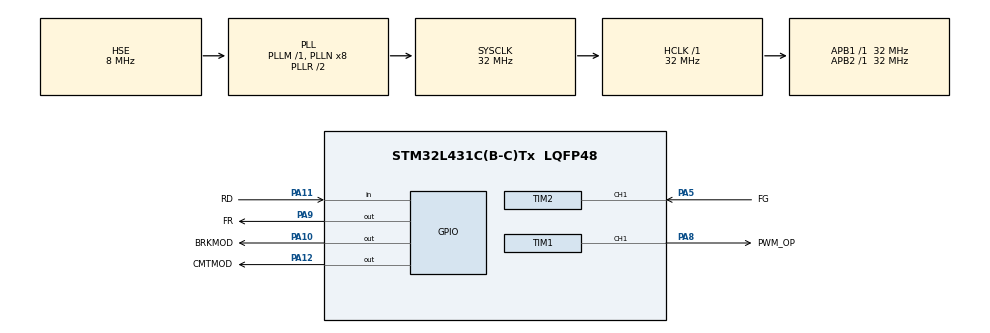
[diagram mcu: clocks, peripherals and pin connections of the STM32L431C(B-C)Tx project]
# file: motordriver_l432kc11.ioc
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Mcu.Family=STM32L4
Mcu.Name=STM32L431C(B-C)Tx
Mcu.Package=LQFP48
NVIC.PriorityGroup=NVIC_PRIORITYGROUP_4
NVIC.TIM2_IRQn=true\:0\:0\:false\:false\:true\:true\:true\:true
PA10.GPIO_Label=BRKMOD
PA10.Signal=GPIO_Output
PA11.GPIO_Label=RD
PA11.Signal=GPIO_Input
PA12.GPIO_Label=CMTMOD
PA12.Signal=GPIO_Output
PA13\ (JTMS-SWDIO).Mode=JTAG_5_pins
PA13\ (JTMS-SWDIO).Signal=SYS_JTMS-SWDIO
PA14\ (JTCK-SWCLK).Mode=JTAG_5_pins
PA14\ (JTCK-SWCLK).Signal=SYS_JTCK-SWCLK
PA15\ (JTDI).Mode=JTAG_5_pins
PA15\ (JTDI).Signal=SYS_JTDI
PA5.GPIO_Label=FG
PA5.Signal=S_TIM2_CH1
PA8.GPIO_Label=PWM_OP
PA8.Signal=S_TIM1_CH1
PA9.GPIO_Label=FR
PA9.Signal=GPIO_Output
PB3\ (JTDO-TRACESWO).Mode=JTAG_5_pins
PB3\ (JTDO-TRACESWO).Signal=SYS_JTDO-SWO
PB4\ (NJTRST).Mode=JTAG_5_pins
PB4\ (NJTRST).Signal=SYS_JTRST
PH0-OSC_IN\ (PH0).Mode=HSE-External-Oscillator
PH0-OSC_IN\ (PH0).Signal=RCC_OSC_IN
PH1-OSC_OUT\ (PH1).Mode=HSE-External-Oscillator
PH1-OSC_OUT\ (PH1).Signal=RCC_OSC_OUT
ProjectManager.HeapSize=0x200
ProjectManager.StackSize=0x400
ProjectManager.TargetToolchain=STM32CubeIDE
RCC.ADCFreq_Value=32000000
RCC.AHBFreq_Value=32000000
RCC.APB1Freq_Value=32000000
RCC.APB1TimFreq_Value=32000000
RCC.APB2Freq_Value=32000000
RCC.APB2TimFreq_Value=32000000
RCC.CortexFreq_Value=32000000
RCC.HCLKFreq_Value=32000000
RCC.HSE_VALUE=8000000
RCC.HSI48_VALUE=48000000
RCC.HSI_VALUE=16000000
RCC.LSE_VALUE=32768
RCC.MSI_VALUE=4000000
RCC.PLLSourceVirtual=RCC_PLLSOURCE_HSE
RCC.SYSCLKFreq_VALUE=32000000
RCC.SYSCLKSource=RCC_SYSCLKSOURCE_PLLCLK
RCC.VCOOutputFreq_Value=64000000
SH.S_TIM1_CH1.0=TIM1_CH1,PWM Generation1 CH1
SH.S_TIM2_CH1.0=TIM2_CH1,Input_Capture1_from_TI1
TIM1.Channel-PWM\ Generation1\ CH1=TIM_CHANNEL_1
TIM1.Period=100-1
TIM1.Prescaler=32-1
TIM2.Channel-Input_Capture1_from_TI1=TIM_CHANNEL_1
TIM2.ICPolarity_CH1=TIM_INPUTCHANNELPOLARITY_BOTHEDGE
TIM2.Prescaler=32-1
VP_TIM1_VS_ClockSourceINT.Mode=Internal
VP_TIM2_VS_ClockSourceINT.Mode=Internal
board=custom

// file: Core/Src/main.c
/* USER CODE BEGIN Header */
/**
  ******************************************************************************
  * @file           : main.c
  * @brief          : Main program body
  ******************************************************************************
  * @attention
  *
  * Copyright (c) 2024 STMicroelectronics.
  * All rights reserved.
  *
  * This software is licensed under terms that can be found in the LICENSE file
  * in the root directory of this software component.
  * If no LICENSE file comes with this software, it is provided AS-IS.
  *
  ******************************************************************************
  */
/* USER CODE END Header */
#include "main.h"

/* USER CODE BEGIN Includes */
#include "motordriver.h"
/* USER CODE END Includes */

TIM_HandleTypeDef htim1;
TIM_HandleTypeDef htim2;

void SystemClock_Config(void);
static void MX_GPIO_Init(void);
static void MX_TIM1_Init(void);
static void MX_TIM2_Init(void);

int main(void)
{

  /* MCU Configuration--------------------------------------------------------*/

  /* Reset of all peripherals, Initializes the Flash interface and the Systick. */
  HAL_Init();

  /* Configure the system clock */
  SystemClock_Config();

  /* Initialize all configured peripherals */
  MX_GPIO_Init();
  MX_TIM1_Init();
  MX_TIM2_Init();
  /* USER CODE BEGIN 2 */
  set_desired_motorx(50,1);
  HAL_Delay(5000);
  stop_motor_x();
  /* USER CODE END 2 */

  /* Infinite loop */
  while (1)
  {

  }
}

void SystemClock_Config(void)
{
  RCC_OscInitTypeDef RCC_OscInitStruct = {0};
  RCC_ClkInitTypeDef RCC_ClkInitStruct = {0};

  /** Configure the main internal regulator output voltage
  */
  if (HAL_PWREx_ControlVoltageScaling(PWR_REGULATOR_VOLTAGE_SCALE1) != HAL_OK)
  {
    Error_Handler();
  }

  /** Initializes the RCC Oscillators according to the specified parameters
  * in the RCC_OscInitTypeDef structure.
  */
  RCC_OscInitStruct.OscillatorType = RCC_OSCILLATORTYPE_HSE;
  RCC_OscInitStruct.HSEState = RCC_HSE_ON;
  RCC_OscInitStruct.PLL.PLLState = RCC_PLL_ON;
  RCC_OscInitStruct.PLL.PLLSource = RCC_PLLSOURCE_HSE;
  RCC_OscInitStruct.PLL.PLLM = 1;
  RCC_OscInitStruct.PLL.PLLN = 8;
  RCC_OscInitStruct.PLL.PLLP = RCC_PLLP_DIV7;
  RCC_OscInitStruct.PLL.PLLQ = RCC_PLLQ_DIV2;
  RCC_OscInitStruct.PLL.PLLR = RCC_PLLR_DIV2;
  if (HAL_RCC_OscConfig(&RCC_OscInitStruct) != HAL_OK)
  {
    Error_Handler();
  }

  /** Initializes the CPU, AHB and APB buses clocks
  */
  RCC_ClkInitStruct.ClockType = RCC_CLOCKTYPE_HCLK|RCC_CLOCKTYPE_SYSCLK
                              |RCC_CLOCKTYPE_PCLK1|RCC_CLOCKTYPE_PCLK2;
  RCC_ClkInitStruct.SYSCLKSource = RCC_SYSCLKSOURCE_PLLCLK;
  RCC_ClkInitStruct.AHBCLKDivider = RCC_SYSCLK_DIV1;
  RCC_ClkInitStruct.APB1CLKDivider = RCC_HCLK_DIV1;
  RCC_ClkInitStruct.APB2CLKDivider = RCC_HCLK_DIV1;

  if (HAL_RCC_ClockConfig(&RCC_ClkInitStruct, FLASH_LATENCY_1) != HAL_OK)
  {
    Error_Handler();
  }
}

static void MX_TIM1_Init(void)
{

  TIM_ClockConfigTypeDef sClockSourceConfig = {0};
  TIM_MasterConfigTypeDef sMasterConfig = {0};
  TIM_OC_InitTypeDef sConfigOC = {0};
  TIM_BreakDeadTimeConfigTypeDef sBreakDeadTimeConfig = {0};

  htim1.Instance = TIM1;
  htim1.Init.Prescaler = 32-1;
  htim1.Init.CounterMode = TIM_COUNTERMODE_UP;
  htim1.Init.Period = 100-1;
  htim1.Init.ClockDivision = TIM_CLOCKDIVISION_DIV1;
  htim1.Init.RepetitionCounter = 0;
  htim1.Init.AutoReloadPreload = TIM_AUTORELOAD_PRELOAD_DISABLE;
  if (HAL_TIM_Base_Init(&htim1) != HAL_OK)
  {
    Error_Handler();
  }
  sClockSourceConfig.ClockSource = TIM_CLOCKSOURCE_INTERNAL;
  if (HAL_TIM_ConfigClockSource(&htim1, &sClockSourceConfig) != HAL_OK)
  {
    Error_Handler();
  }
  if (HAL_TIM_PWM_Init(&htim1) != HAL_OK)
  {
    Error_Handler();
  }
  sMasterConfig.MasterOutputTrigger = TIM_TRGO_RESET;
  sMasterConfig.MasterOutputTrigger2 = TIM_TRGO2_RESET;
  sMasterConfig.MasterSlaveMode = TIM_MASTERSLAVEMODE_DISABLE;
  if (HAL_TIMEx_MasterConfigSynchronization(&htim1, &sMasterConfig) != HAL_OK)
  {
    Error_Handler();
  }
  sConfigOC.OCMode = TIM_OCMODE_PWM1;
  sConfigOC.Pulse = 0;
  sConfigOC.OCPolarity = TIM_OCPOLARITY_HIGH;
  sConfigOC.OCNPolarity = TIM_OCNPOLARITY_HIGH;
  sConfigOC.OCFastMode = TIM_OCFAST_DISABLE;
  sConfigOC.OCIdleState = TIM_OCIDLESTATE_RESET;
  sConfigOC.OCNIdleState = TIM_OCNIDLESTATE_RESET;
  if (HAL_TIM_PWM_ConfigChannel(&htim1, &sConfigOC, TIM_CHANNEL_1) != HAL_OK)
  {
    Error_Handler();
  }
  sBreakDeadTimeConfig.OffStateRunMode = TIM_OSSR_DISABLE;
  sBreakDeadTimeConfig.OffStateIDLEMode = TIM_OSSI_DISABLE;
  sBreakDeadTimeConfig.LockLevel = TIM_LOCKLEVEL_OFF;
  sBreakDeadTimeConfig.DeadTime = 0;
  sBreakDeadTimeConfig.BreakState = TIM_BREAK_DISABLE;
  sBreakDeadTimeConfig.BreakPolarity = TIM_BREAKPOLARITY_HIGH;
  sBreakDeadTimeConfig.BreakFilter = 0;
  sBreakDeadTimeConfig.Break2State = TIM_BREAK2_DISABLE;
  sBreakDeadTimeConfig.Break2Polarity = TIM_BREAK2POLARITY_HIGH;
  sBreakDeadTimeConfig.Break2Filter = 0;
  sBreakDeadTimeConfig.AutomaticOutput = TIM_AUTOMATICOUTPUT_DISABLE;
  if (HAL_TIMEx_ConfigBreakDeadTime(&htim1, &sBreakDeadTimeConfig) != HAL_OK)
  {
    Error_Handler();
  }
  HAL_TIM_MspPostInit(&htim1);

}

static void MX_TIM2_Init(void)
{

  TIM_ClockConfigTypeDef sClockSourceConfig = {0};
  TIM_MasterConfigTypeDef sMasterConfig = {0};
  TIM_IC_InitTypeDef sConfigIC = {0};

  htim2.Instance = TIM2;
  htim2.Init.Prescaler = 32-1;
  htim2.Init.CounterMode = TIM_COUNTERMODE_UP;
  htim2.Init.Period = 4294967295;
  htim2.Init.ClockDivision = TIM_CLOCKDIVISION_DIV1;
  htim2.Init.AutoReloadPreload = TIM_AUTORELOAD_PRELOAD_DISABLE;
  if (HAL_TIM_Base_Init(&htim2) != HAL_OK)
  {
    Error_Handler();
  }
  sClockSourceConfig.ClockSource = TIM_CLOCKSOURCE_INTERNAL;
  if (HAL_TIM_ConfigClockSource(&htim2, &sClockSourceConfig) != HAL_OK)
  {
    Error_Handler();
  }
  if (HAL_TIM_IC_Init(&htim2) != HAL_OK)
  {
    Error_Handler();
  }
  sMasterConfig.MasterOutputTrigger = TIM_TRGO_RESET;
  sMasterConfig.MasterSlaveMode = TIM_MASTERSLAVEMODE_DISABLE;
  if (HAL_TIMEx_MasterConfigSynchronization(&htim2, &sMasterConfig) != HAL_OK)
  {
    Error_Handler();
  }
  sConfigIC.ICPolarity = TIM_INPUTCHANNELPOLARITY_BOTHEDGE;
  sConfigIC.ICSelection = TIM_ICSELECTION_DIRECTTI;
  sConfigIC.ICPrescaler = TIM_ICPSC_DIV1;
  sConfigIC.ICFilter = 0;
  if (HAL_TIM_IC_ConfigChannel(&htim2, &sConfigIC, TIM_CHANNEL_1) != HAL_OK)
  {
    Error_Handler();
  }

}

static void MX_GPIO_Init(void)
{
  GPIO_InitTypeDef GPIO_InitStruct = {0};

  /* GPIO Ports Clock Enable */
  __HAL_RCC_GPIOH_CLK_ENABLE();
  __HAL_RCC_GPIOA_CLK_ENABLE();
  __HAL_RCC_GPIOB_CLK_ENABLE();

  /*Configure GPIO pin Output Level */
  HAL_GPIO_WritePin(GPIOA, FR_Pin|BRKMOD_Pin|CMTMOD_Pin, GPIO_PIN_RESET);

  /*Configure GPIO pins : FR_Pin BRKMOD_Pin CMTMOD_Pin */
  GPIO_InitStruct.Pin = FR_Pin|BRKMOD_Pin|CMTMOD_Pin;
  GPIO_InitStruct.Mode = GPIO_MODE_OUTPUT_PP;
  GPIO_InitStruct.Pull = GPIO_NOPULL;
  GPIO_InitStruct.Speed = GPIO_SPEED_FREQ_LOW;
  HAL_GPIO_Init(GPIOA, &GPIO_InitStruct);

  /*Configure GPIO pin : RD_Pin */
  GPIO_InitStruct.Pin = RD_Pin;
  GPIO_InitStruct.Mode = GPIO_MODE_INPUT;
  GPIO_InitStruct.Pull = GPIO_NOPULL;
  HAL_GPIO_Init(RD_GPIO_Port, &GPIO_InitStruct);

/* USER CODE BEGIN MX_GPIO_Init_2 */
  motor_initialize(&GPIO_InitStruct);
/* USER CODE END MX_GPIO_Init_2 */
}

void Error_Handler(void)
{
  __disable_irq();
  while (1)
  {
  }
}
